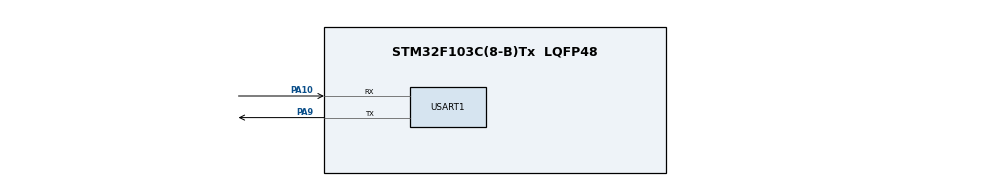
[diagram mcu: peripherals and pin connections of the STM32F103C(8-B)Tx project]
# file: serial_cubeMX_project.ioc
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Mcu.Family=STM32F1
Mcu.Name=STM32F103C(8-B)Tx
Mcu.Package=LQFP48
NVIC.PriorityGroup=NVIC_PRIORITYGROUP_4
NVIC.USART1_IRQn=true\:0\:0\:false\:false\:true\:true\:true
PA10.Mode=Asynchronous
PA10.Signal=USART1_RX
PA9.Mode=Asynchronous
PA9.Signal=USART1_TX
PD0-OSC_IN.Mode=HSE-External-Oscillator
PD0-OSC_IN.Signal=RCC_OSC_IN
PD1-OSC_OUT.Mode=HSE-External-Oscillator
PD1-OSC_OUT.Signal=RCC_OSC_OUT
ProjectManager.HeapSize=0x200
ProjectManager.StackSize=0x400
ProjectManager.TargetToolchain=MDK-ARM V5.32
RCC.APB1Freq_Value=8000000
RCC.APB2Freq_Value=8000000
RCC.SYSCLKSource=RCC_SYSCLKSOURCE_HSE
USART1.VirtualMode=VM_ASYNC
VP_SYS_VS_ND.Mode=No_Debug
board=custom

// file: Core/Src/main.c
/* USER CODE BEGIN Header */
/**
  ******************************************************************************
  * @file           : main.c
  * @brief          : Main program body
  ******************************************************************************
  * @attention
  *
  * <h2><center>&copy; Copyright (c) 2025 STMicroelectronics.
  * All rights reserved.</center></h2>
  *
  * This software component is licensed by ST under BSD 3-Clause license,
  * the "License"; You may not use this file except in compliance with the
  * License. You may obtain a copy of the License at:
  *                        opensource.org/licenses/BSD-3-Clause
  *
  ******************************************************************************
  */
/* USER CODE END Header */
#include "main.h"
#include "usart.h"
#include "gpio.h"

/* USER CODE BEGIN Includes */
#include <string.h>
/* USER CODE END Includes */

/* USER CODE BEGIN PV */
// 实验变量定义
char *message = "hello windows!\r\n";
uint16_t msg_len = 0;
uint8_t send_enabled = 1;      // 发送使能标志
uint8_t rx_buffer;             // 接收缓冲区
/* USER CODE END PV */

void SystemClock_Config(void);

int main(void)
{

  /* MCU Configuration--------------------------------------------------------*/

  /* Reset of all peripherals, Initializes the Flash interface and the Systick. */
  HAL_Init();

  /* Configure the system clock */
  SystemClock_Config();

  /* Initialize all configured peripherals */
  MX_GPIO_Init();
  MX_USART1_UART_Init();
  /* USER CODE BEGIN 2 */
  // 计算消息长度
  msg_len = strlen(message);

  // 发送启动信息
  HAL_UART_Transmit(&huart1, (uint8_t*)"Experiment Started!\r\n", 21, HAL_MAX_DELAY);
  HAL_UART_Transmit(&huart1, (uint8_t*)"Continuous sending 'hello windows!'\r\n", 36, HAL_MAX_DELAY);
  HAL_UART_Transmit(&huart1, (uint8_t*)"Send '#' to stop, '*' to start\r\n", 31, HAL_MAX_DELAY);
  HAL_UART_Transmit(&huart1, (uint8_t*)"==============================\r\n", 32, HAL_MAX_DELAY);
  /* USER CODE END 2 */

  /* Infinite loop */
  while (1)
  {

    /* USER CODE BEGIN 3 */
    // 实验1：轮询发送（不加延时）
    if (send_enabled) {
        HAL_UART_Transmit(&huart1, (uint8_t*)message, msg_len, HAL_MAX_DELAY);
    }

    // 实验2：轮询接收控制字符（非阻塞方式）
    if (HAL_UART_Receive(&huart1, &rx_buffer, 1, 0) == HAL_OK) {
        // 成功接收到字符
        switch (rx_buffer) {
            case '#':   // 停止发送
                if (send_enabled) {
                    send_enabled = 0;
                    HAL_UART_Transmit(&huart1, (uint8_t*)"\r\n--- STOPPED ---\r\n\r\n", 22, HAL_MAX_DELAY);
                }
                break;

            case '*':   // 开始发送
                if (!send_enabled) {
                    send_enabled = 1;
                    HAL_UART_Transmit(&huart1, (uint8_t*)"\r\n--- STARTED ---\r\n\r\n", 22, HAL_MAX_DELAY);
                }
                break;

            default:    // 其他字符，可选回显
                // 可以取消注释下面的行来回显接收到的字符
                // HAL_UART_Transmit(&huart1, (uint8_t*)"Rx: ", 4, HAL_MAX_DELAY);
                // HAL_UART_Transmit(&huart1, &rx_buffer, 1, HAL_MAX_DELAY);
                // HAL_UART_Transmit(&huart1, (uint8_t*)"\r\n", 2, HAL_MAX_DELAY);
                break;
        }
    }
  }
  /* USER CODE END 3 */
}

void SystemClock_Config(void)
{
  RCC_OscInitTypeDef RCC_OscInitStruct = {0};
  RCC_ClkInitTypeDef RCC_ClkInitStruct = {0};

  /** Initializes the RCC Oscillators according to the specified parameters
  * in the RCC_OscInitTypeDef structure.
  */
  RCC_OscInitStruct.OscillatorType = RCC_OSCILLATORTYPE_HSE;
  RCC_OscInitStruct.HSEState = RCC_HSE_ON;
  RCC_OscInitStruct.PLL.PLLState = RCC_PLL_NONE;
  if (HAL_RCC_OscConfig(&RCC_OscInitStruct) != HAL_OK)
  {
    Error_Handler();
  }
  /** Initializes the CPU, AHB and APB buses clocks
  */
  RCC_ClkInitStruct.ClockType = RCC_CLOCKTYPE_HCLK|RCC_CLOCKTYPE_SYSCLK
                              |RCC_CLOCKTYPE_PCLK1|RCC_CLOCKTYPE_PCLK2;
  RCC_ClkInitStruct.SYSCLKSource = RCC_SYSCLKSOURCE_HSE;
  RCC_ClkInitStruct.AHBCLKDivider = RCC_SYSCLK_DIV1;
  RCC_ClkInitStruct.APB1CLKDivider = RCC_HCLK_DIV1;
  RCC_ClkInitStruct.APB2CLKDivider = RCC_HCLK_DIV1;

  if (HAL_RCC_ClockConfig(&RCC_ClkInitStruct, FLASH_LATENCY_0) != HAL_OK)
  {
    Error_Handler();
  }
}

void Error_Handler(void)
{
  __disable_irq();
  while (1)
  {
  }
}

/************************ (C) COPYRIGHT STMicroelectronics *****END OF FILE****/
